# STM32G070 register map
File version: 1.4
CPU: CM0 r0p1, little endian, MPU, no FPU, 2 interrupt priority bits
Registers are 32-bit, read-write, reset 0x0 unless marked. A register's access mark holds for its fields unless they carry their own. Offsets are from the block's base; [hi:lo] are bit positions; lines under a group give offsets from that group; {n}, {i} and the like mark numbered series.

## DMA — DMA controller
Base 0x40020000
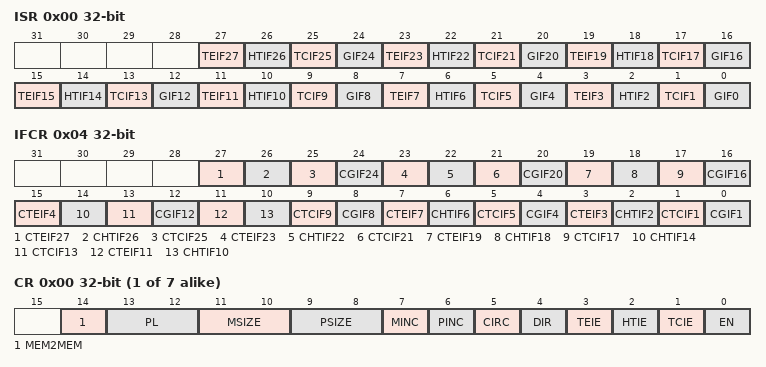
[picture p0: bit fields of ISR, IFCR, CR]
0x00 ISR ro — low interrupt status register
  [27] TEIF27 — Channel transfer error flag
  [26] HTIF26 — Channel half transfer flag
  [25] TCIF25 — Channel transfer complete flag
  [24] GIF24 — Channel global interrupt flag
  [23] TEIF23 — Channel transfer error flag
  [22] HTIF22 — Channel half transfer flag
  [21] TCIF21 — Channel transfer complete flag
  [20] GIF20 — Channel global interrupt flag
  [19] TEIF19 — Channel transfer error flag
  [18] HTIF18 — Channel half transfer flag
  [17] TCIF17 — Channel transfer complete flag
  [16] GIF16 — Channel global interrupt flag
  [15] TEIF15 — Channel transfer error flag
  [14] HTIF14 — Channel half transfer flag
  [13] TCIF13 — Channel transfer complete flag
  [12] GIF12 — Channel global interrupt flag
  [11] TEIF11 — Channel transfer error flag
  [10] HTIF10 — Channel half transfer flag
  [9] TCIF9 — Channel transfer complete flag
  [8] GIF8 — Channel global interrupt flag
  [7] TEIF7 — Channel 7 transfer error flag
  [6] HTIF6 — Channel 6 half transfer flag
  [5] TCIF5 — Channel 5 transfer complete flag
  [4] GIF4 — Channel 4 global interrupt flag
  [3] TEIF3 — Channel 3 transfer error flag
  [2] HTIF2 — Channel 2 half transfer flag
  [1] TCIF1 — Channel 1 transfer complete flag
  [0] GIF0 — Channel global interrupt flag
0x04 IFCR wo — high interrupt status register
  [27] CTEIF27 — Channel transfer error flag
  [26] CHTIF26 — Channel half transfer flag
  [25] CTCIF25 — Channel transfer complete flag
  [24] CGIF24 — Channel global interrupt flag
  [23] CTEIF23 — Channel transfer error flag
  [22] CHTIF22 — Channel half transfer flag
  [21] CTCIF21 — Channel transfer complete flag
  [20] CGIF20 — Channel global interrupt flag
  [19] CTEIF19 — Channel transfer error flag
  [18] CHTIF18 — Channel half transfer flag
  [17] CTCIF17 — Channel transfer complete flag
  [16] CGIF16 — Channel global interrupt flag
  [15] CTEIF4 — Clear channel 4 transfer error flag
  [14] CHTIF14 — Channel half transfer flag
  [13] CTCIF13 — Channel transfer complete flag
  [12] CGIF12 — Channel global interrupt flag
  [11] CTEIF11 — Channel transfer error flag
  [10] CHTIF10 — Channel half transfer flag
  [9] CTCIF9 — Channel transfer complete flag
  [8] CGIF8 — Channel global interrupt flag
  [7] CTEIF7 — Clear channel 7 transfer error flag
  [6] CHTIF6 — Clear channel 6 half transfer flag
  [5] CTCIF5 — Clear channel 5 transfer complete flag
  [4] CGIF4 — Clear channel 4 global interrupt flag
  [3] CTEIF3 — Clear channel 3 transfer error flag
  [2] CHTIF2 — Clear channel 2 half transfer flag
  [1] CTCIF1 — Clear channel 1 transfer complete flag
  [0] CGIF1 — Clear channel 1 global interrupt flag
0x08 CH{i} (i=1..7; step 0x14) group — Channel cluster: CCR?, CNDTR?, CPAR?, and CMAR? registers
  0x00 CR — DMA channel x configuration register
    [14] MEM2MEM — Memory to memory mode
    [13:12] PL — Channel priority level
    [11:10] MSIZE — Memory size
    [9:8] PSIZE — Peripheral size
    [7] MINC — Memory increment mode
    [6] PINC — Peripheral increment mode
    [5] CIRC — Circular mode
    [4] DIR — Data transfer direction
    [3] TEIE — Transfer error interrupt enable
    [2] HTIE — Half transfer interrupt enable
    [1] TCIE — Transfer complete interrupt enable
    [0] EN — Channel enable
  0x04 NDTR — DMA channel x number of data register
    [15:0] NDT — Number of data to transfer
  0x08 PAR — DMA channel x peripheral address register
    [31:0] PA — Peripheral address
  0x0C MAR — DMA channel x memory address register
    [31:0] MA — Memory address

## DMAMUX
Base 0x40020800
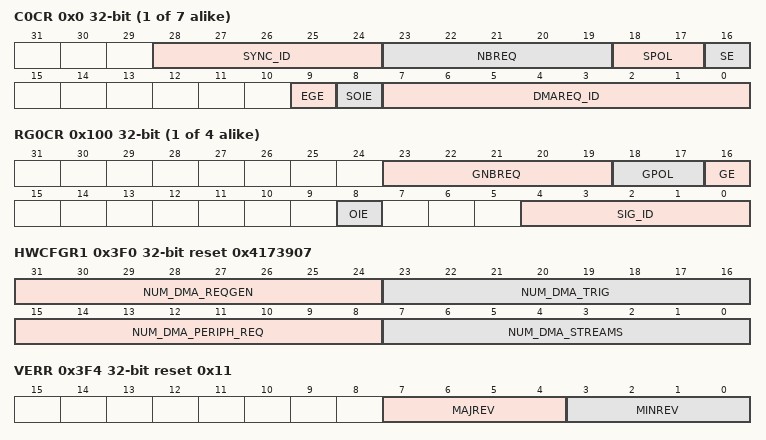
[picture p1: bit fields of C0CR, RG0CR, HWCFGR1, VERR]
{0x0+4i} C{i}CR (i=0..6) — DMAMux - DMA request line multiplexer channel x control register
  [28:24] SYNC_ID — Synchronization input selected
  [23:19] NBREQ — Number of DMA requests to forward Defines the number of DMA requests forwarded before output event is generated. In synchronous mode, it also defines the number of DMA requests to forward after a synchronization event, then stop forwarding. The actual number of DMA requests forwarded is NBREQ+1. Note: This field can only be written when both SE and EGE bits are reset.
  [18:17] SPOL — Synchronization event type selector Defines the synchronization event on the selected synchronization input:
  [16] SE — Synchronous operating mode enable/disable
  [9] EGE — Event generation enable/disable
  [8] SOIE — Interrupt enable at synchronization event overrun
  [7:0] DMAREQ_ID — Input DMA request line selected
0x80 CSR ro — DMAMUX request line multiplexer interrupt channel status register
  [6:0] SOF — Synchronization overrun event flag
0x84 CFR wo — DMAMUX request line multiplexer interrupt clear flag register
  [6:0] CSOF — Clear synchronization overrun event flag
{0x100+4i} RG{i}CR (i=0..3) — DMAMux - DMA request generator channel x control register
  [23:19] GNBREQ — Number of DMA requests to generate Defines the number of DMA requests generated after a trigger event, then stop generating. The actual number of generated DMA requests is GNBREQ+1. Note: This field can only be written when GE bit is reset.
  [18:17] GPOL — DMA request generator trigger event type selection Defines the trigger event on the selected DMA request trigger input
  [16] GE — DMA request generator channel enable/disable
  [8] OIE — Interrupt enable at trigger event overrun
  [4:0] SIG_ID — DMA request trigger input selected
0x140 RGSR ro — DMAMux - DMA request generator status register
  [3:0] OF — Trigger event overrun flag The flag is set when a trigger event occurs on DMA request generator channel x, while the DMA request generator counter value is lower than GNBREQ. The flag is cleared by writing 1 to the corresponding COFx bit in DMAMUX_RGCFR register.
0x144 RGCFR wo — DMAMux - DMA request generator clear flag register
  [3:0] COF — Clear trigger event overrun flag Upon setting, this bit clears the corresponding overrun flag OFx in the DMAMUX_RGCSR register.
0x3EC HWCFGR2 ro reset 0x17 — DMAMUX hardware configuration 2 register
  [7:0] NUM_DMA_EXT_REQ — Number of DMA request trigger inputs
0x3F0 HWCFGR1 ro reset 0x4173907 — DMAMUX hardware configuration 1 register
  [31:24] NUM_DMA_REQGEN — number of DMA request generator channels
  [23:16] NUM_DMA_TRIG — number of synchronization inputs
  [15:8] NUM_DMA_PERIPH_REQ — number of DMA request lines from peripherals
  [7:0] NUM_DMA_STREAMS — number of DMA request line multiplexer (output) channels
0x3F4 VERR ro reset 0x11 — DMAMUX version register
  [7:4] MAJREV — Major IP revision
  [3:0] MINREV — Minor IP revision
0x3F8 IPIDR ro reset 0x100011 — DMAMUX IP identification register
  [31:0] ID — IP identification
0x3FC SIDR ro reset 0xA3C5DD01 — DMAMUX size identification register
  [31:0] SID — Size identification

## Notices in the file
Copyright (c) 2020 STMicroelectronics.
SPDX-License-Identifier: Apache-2.0
Licensed under the Apache License, Version 2.0 (the "License");
you may not use this file except in compliance with the License.
You may obtain a copy of the License at
http://www.apache.org/licenses/LICENSE-2.0
Unless required by applicable law or agreed to in writing, software
distributed under the License is distributed on an "AS IS" BASIS,
WITHOUT WARRANTIES OR CONDITIONS OF ANY KIND, either express or implied.
See the License for the specific language governing permissions and
limitations under the License.
